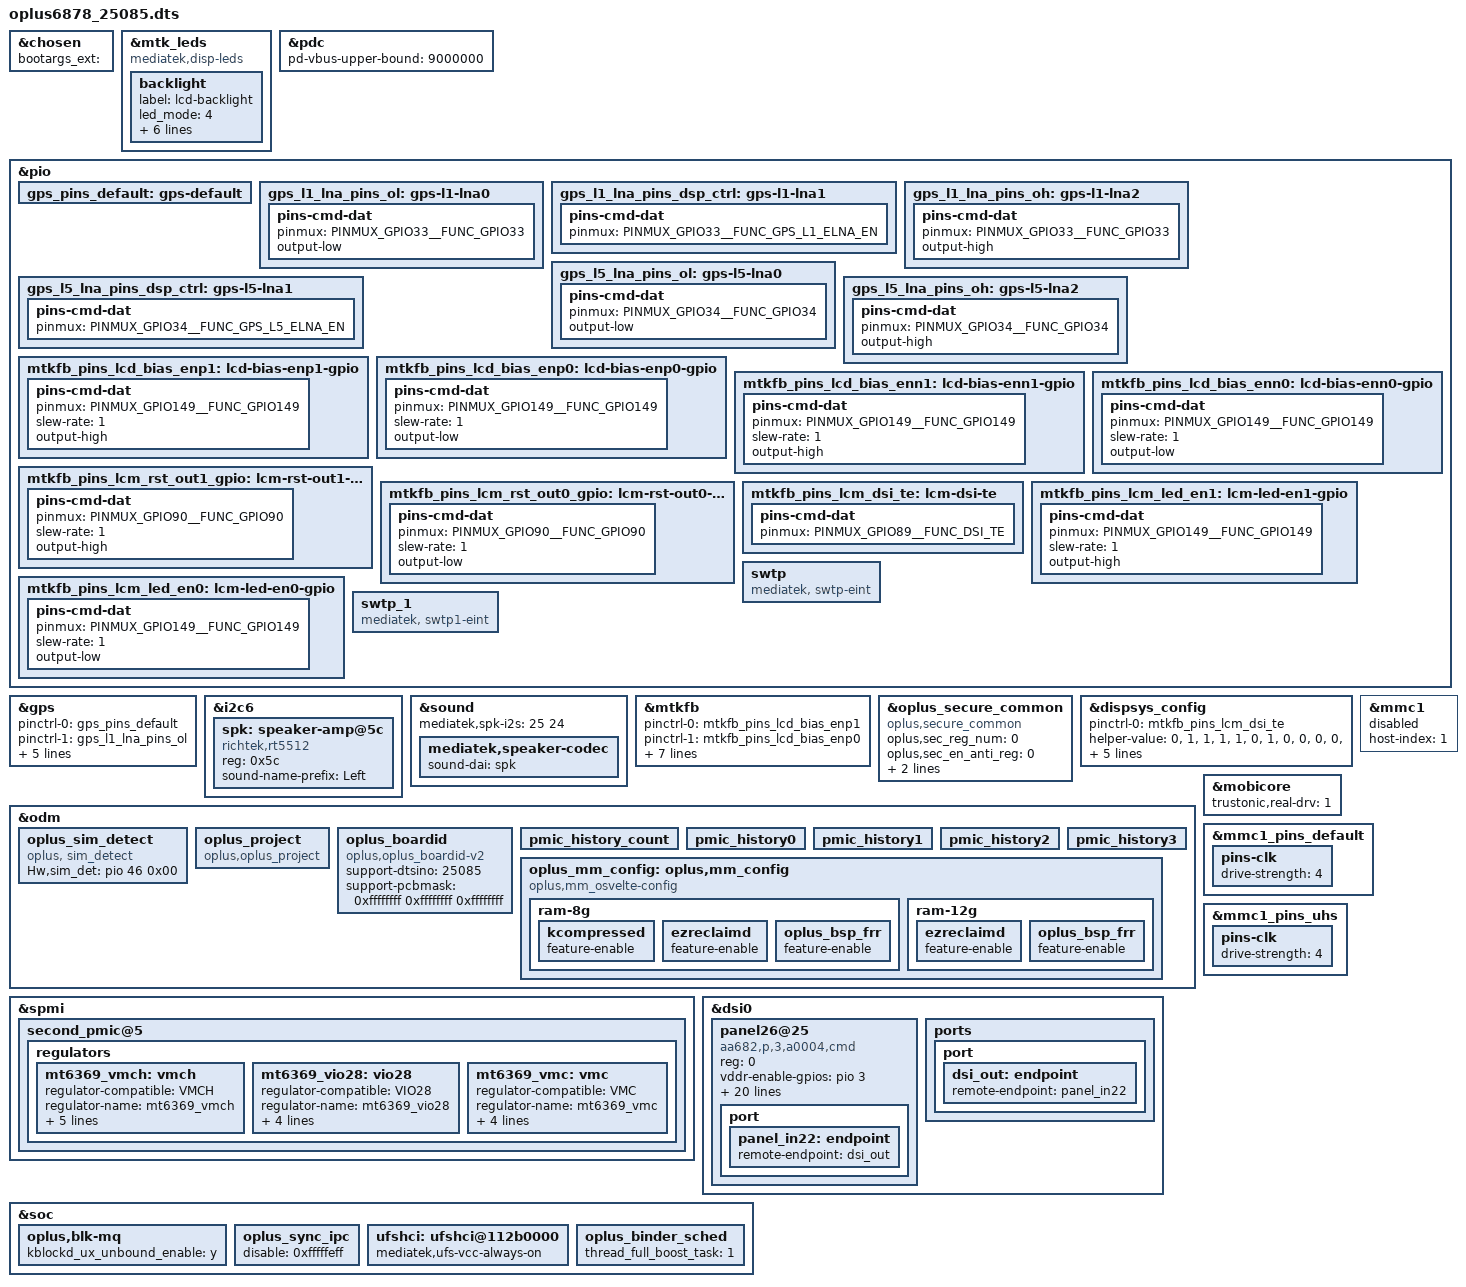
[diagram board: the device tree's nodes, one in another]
// SPDX-License-Identifier: (GPL-2.0 OR MIT)

/*
 * Copyright (C) 2022 MediaTek Inc.
 */
/dts-v1/;
/plugin/;
#include <dt-bindings/interrupt-controller/arm-gic.h>
#include <dt-bindings/interrupt-controller/irq.h>
#include <dt-bindings/phy/phy.h>
#include <dt-bindings/pinctrl/mt6878-pinfunc.h>
#include "mediatek/nfc/mt6878_Jinx-M_thn31s.dtsi"
#include "mediatek/kjinxm_regulator_wl2866d.dtsi"
#if 0
#include <dt-bindings/pinctrl/mt6897-pinfunc.h>
#endif

/* #ifdef OPLUS_FEATURE_SENSOR */
#include "mediatek/oplus_sensor_25085.dtsi"
/* #endif */

/* #ifdef OPLUS_FEATURE_SENSOR */
#include "mediatek/oplus_misc_25085.dtsi"
/* #endif */

/* #ifdef OPLUS_FEATURE_CHG_BASIC */
#include "mediatek/oplus_charge_jinxm_domestic.dtsi"
/* #endif */

/* #ifdef OPLUS_FEATURE_FINGERPRINT */
#include "mediatek/oplus_uff_25085_25329.dtsi"
/* #endif */

/* Add for jinx-m pt device-tree */
#include "mediatek/oplus_pt_25085.dtsi"

&chosen {
bootargs_ext = "";
};

&mtk_leds {
	compatible = "mediatek,disp-leds";
	status = "okay";

	backlight {
		label = "lcd-backlight";
		led_mode = <4>;
		min-brightness = <1>;
		max-brightness = <4094>;
		max-hw-brightness = <4094>;
		led-bits = <13>;
		trans-bits = <13>;
		default-state = "half";
	};
};

&pdc {
	pd-vbus-upper-bound = <9000000>;
};

#if 0

&connfem {
/* Enable epa_elna node to support Wifi & BT ePA/eLNA FEM on customer load */
#if 0
	epa-elna {
		parts = <&wlan7207h &wlan7207c>;
		wifi {
			flags-0 {
				open-loop;
			};
		};
		bt {
			flags-0 {
				/* choose one of: epa-elna/epa/elna/bypass */
				epa-elna;
			};
		};
	};
#endif
};
#endif

/* GPS GPIO standardization start */
&pio {
	gps_pins_default: gps-default {
	};
	gps_l1_lna_pins_ol: gps-l1-lna0 {
		pins-cmd-dat {
			pinmux = <PINMUX_GPIO33__FUNC_GPIO33>;
			output-low;
		};
	};
	gps_l1_lna_pins_dsp_ctrl: gps-l1-lna1 {
		pins-cmd-dat {
			pinmux = <PINMUX_GPIO33__FUNC_GPS_L1_ELNA_EN>;
		};
	};
	gps_l1_lna_pins_oh: gps-l1-lna2 {
		pins-cmd-dat {
			pinmux = <PINMUX_GPIO33__FUNC_GPIO33>;
			output-high;
		};
	};
	gps_l5_lna_pins_ol: gps-l5-lna0 {
		pins-cmd-dat {
			pinmux = <PINMUX_GPIO34__FUNC_GPIO34>;
			output-low;
		};
	};
	gps_l5_lna_pins_dsp_ctrl: gps-l5-lna1 {
		pins-cmd-dat {
			pinmux = <PINMUX_GPIO34__FUNC_GPS_L5_ELNA_EN>;
		};
	};
	gps_l5_lna_pins_oh: gps-l5-lna2 {
		pins-cmd-dat {
			pinmux = <PINMUX_GPIO34__FUNC_GPIO34>;
			output-high;
		};
	};
};
&gps {
	pinctrl-names = "default",
		"gps_l1_lna_disable",
		"gps_l1_lna_dsp_ctrl",
		"gps_l1_lna_enable",
		"gps_l5_lna_disable",
		"gps_l5_lna_dsp_ctrl",
		"gps_l5_lna_enable";
	pinctrl-0 = <&gps_pins_default>;
	pinctrl-1 = <&gps_l1_lna_pins_ol>;
	pinctrl-2 = <&gps_l1_lna_pins_dsp_ctrl>;
	pinctrl-3 = <&gps_l1_lna_pins_oh>;
	pinctrl-4 = <&gps_l5_lna_pins_ol>;
	pinctrl-5 = <&gps_l5_lna_pins_dsp_ctrl>;
	pinctrl-6 = <&gps_l5_lna_pins_oh>;
	status = "okay";
};
/* GPS GPIO standardization end */

&i2c6 {
	spk: speaker-amp@5c {
		compatible = "richtek,rt5512";
		#address-cells = <1>;
		#size-cells = <0>;
		#sound-dai-cells = <0>;
		reg = <0x5c>;
		status = "okay";
		sound-name-prefix = "Left";
	};
};

&sound {
	mediatek,spk-i2s = <25 24>;
	mediatek,speaker-codec {
		sound-dai = <&spk>;
	};
};



&mtkfb {
	pinctrl-names = "lcd_bias_enp1_gpio", "lcd_bias_enp0_gpio",
		"lcd_bias_enn1_gpio", "lcd_bias_enn0_gpio",
		"lcm_rst_out1_gpio", "lcm_rst_out0_gpio",
		"mode_te_te", "lcm_led_en1_gpio", "lcm_led_en0_gpio";
	pinctrl-0 = <&mtkfb_pins_lcd_bias_enp1>;
	pinctrl-1 = <&mtkfb_pins_lcd_bias_enp0>;
	pinctrl-2 = <&mtkfb_pins_lcd_bias_enn1>;
	pinctrl-3 = <&mtkfb_pins_lcd_bias_enn0>;
	pinctrl-4 = <&mtkfb_pins_lcm_rst_out1_gpio>;
	pinctrl-5 = <&mtkfb_pins_lcm_rst_out0_gpio>;
	pinctrl-6 = <&mtkfb_pins_lcm_dsi_te>;
	pinctrl-7 = <&mtkfb_pins_lcm_led_en1>;
	pinctrl-8 = <&mtkfb_pins_lcm_led_en0>;

	status = "okay";
};

&oplus_secure_common {
    compatible = "oplus,secure_common";
    oplus,sec_reg_num = <0>;
    oplus,sec_en_anti_reg = <0>;
    oplus,sec_override1_reg = <0>;
    oplus,override1_en_value = <0>;
};

&pio {
	mtkfb_pins_lcd_bias_enp1: lcd-bias-enp1-gpio {
		pins-cmd-dat {
			pinmux = <PINMUX_GPIO149__FUNC_GPIO149>;
			slew-rate = <1>;
			output-high;
		};
	};

	mtkfb_pins_lcd_bias_enp0: lcd-bias-enp0-gpio {
		pins-cmd-dat {
			pinmux = <PINMUX_GPIO149__FUNC_GPIO149>;
			slew-rate = <1>;
			output-low;
		};
	};

	mtkfb_pins_lcd_bias_enn1: lcd-bias-enn1-gpio {
		pins-cmd-dat {
			pinmux = <PINMUX_GPIO149__FUNC_GPIO149>;
			slew-rate = <1>;
			output-high;
		};
	};

	mtkfb_pins_lcd_bias_enn0: lcd-bias-enn0-gpio {
		pins-cmd-dat {
			pinmux = <PINMUX_GPIO149__FUNC_GPIO149>;
			slew-rate = <1>;
			output-low;
		};
	};

	mtkfb_pins_lcm_rst_out1_gpio: lcm-rst-out1-gpio {
		pins-cmd-dat {
			pinmux = <PINMUX_GPIO90__FUNC_GPIO90>;
			slew-rate = <1>;
			output-high;
		};
	};

	mtkfb_pins_lcm_rst_out0_gpio: lcm-rst-out0-gpio {
		pins-cmd-dat {
			pinmux = <PINMUX_GPIO90__FUNC_GPIO90>;
			slew-rate = <1>;
			output-low;
		};
	};
	mtkfb_pins_lcm_dsi_te: lcm-dsi-te {
		pins-cmd-dat {
			pinmux = <PINMUX_GPIO89__FUNC_DSI_TE>;
		};
	};

	mtkfb_pins_lcm_led_en1: lcm-led-en1-gpio {
		pins-cmd-dat {
			pinmux = <PINMUX_GPIO149__FUNC_GPIO149>;
			slew-rate = <1>;
			output-high;
		};
	};

	mtkfb_pins_lcm_led_en0: lcm-led-en0-gpio {
		pins-cmd-dat {
			pinmux = <PINMUX_GPIO149__FUNC_GPIO149>;
			slew-rate = <1>;
			output-low;
		};
	};
};

&dispsys_config {
	pinctrl-names = "mode_te_te";
	pinctrl-0 = <&mtkfb_pins_lcm_dsi_te>;
	status = "okay";

	helper-value = <0>, /*MTK_DRM_OPT_STAGE*/
				<1>, /*MTK_DRM_OPT_USE_CMDQ*/
				<1>, /*MTK_DRM_OPT_USE_M4U*/
				<1>, /*MTK_DRM_OPT_MMQOS_SUPPORT*/
				<1>, /*MTK_DRM_OPT_MMDVFS_SUPPORT*/
				<0>, /*MTK_DRM_OPT_SODI_SUPPORT*/
				<1>, /*MTK_DRM_OPT_IDLE_MGR*/
				<0>, /*MTK_DRM_OPT_IDLEMGR_SWTCH_DECOUPLE*/
				<0>, /*MTK_DRM_OPT_IDLEMGR_BY_REPAINT*/
				<0>, /*MTK_DRM_OPT_IDLEMGR_ENTER_ULPS*/
				<0>, /*MTK_DRM_OPT_IDLEMGR_KEEP_LP11*/
				<0>, /*MTK_DRM_OPT_DYNAMIC_RDMA_GOLDEN_SETTING*/
				<1>, /*MTK_DRM_OPT_IDLEMGR_DISABLE_ROUTINE_IRQ*/
				<1>, /*MTK_DRM_OPT_IDLEMGR_ASYNC*/
				<0>, /*MTK_DRM_OPT_MET_LOG*/
				<1>, /*MTK_DRM_OPT_USE_PQ*/
				<1>, /*MTK_DRM_OPT_ESD_CHECK_RECOVERY*/
				<1>, /*MTK_DRM_OPT_ESD_CHECK_SWITCH*/
				<1>, /*MTK_DRM_OPT_PRESENT_FENCE*/
				<0>, /*MTK_DRM_OPT_RDMA_UNDERFLOW_AEE*/
				<1>, /*MTK_DRM_OPT_DSI_UNDERRUN_AEE*/
				<0>, /*MTK_DRM_OPT_ODDMR_OD_AEE*/
				<0>, /*MTK_DRM_OPT_ODDMR_DMR_AEE*/
				<1>, /*MTK_DRM_OPT_HRT*/
				<0>, /*MTK_DRM_OPT_HRT_MODE*/
				<0>, /*MTK_DRM_OPT_DELAYED_TRIGGER*/
				<1>, /*MTK_DRM_OPT_OVL_EXT_LAYER*/
				<1>, /*MTK_DRM_OPT_AOD*/
				<1>, /*MTK_DRM_OPT_RPO*/
				<0>, /*MTK_DRM_OPT_DUAL_PIPE*/
				<0>, /*MTK_DRM_OPT_DC_BY_HRT*/
				<0>, /*MTK_DRM_OPT_OVL_WCG*/
				<0>, /*MTK_DRM_OPT_OVL_SBCH*/
				<1>, /*MTK_DRM_OPT_COMMIT_NO_WAIT_VBLANK*/
				<0>, /*MTK_DRM_OPT_MET*/
				<0>, /*MTK_DRM_OPT_REG_PARSER_RAW_DUMP*/
				<0>, /*MTK_DRM_OPT_VP_PQ*/
				<0>, /*MTK_DRM_OPT_GAME_PQ*/
				<0>, /*MTK_DRM_OPT_MMPATH*/
				<0>, /*MTK_DRM_OPT_HBM*/
				<0>, /*MTK_DRM_OPT_VDS_PATH_SWITCH*/
				<0>, /*MTK_DRM_OPT_LAYER_REC*/
				<1>, /*MTK_DRM_OPT_CLEAR_LAYER*/
				<1>, /*MTK_DRM_OPT_LFR*/
				<0>, /*MTK_DRM_OPT_SF_PF*/
				<1>, /*MTK_DRM_OPT_DYN_MIPI_CHANGE*/
				<0>, /*MTK_DRM_OPT_PRIM_DUAL_PIPE*/
				<0>, /*MTK_DRM_OPT_MSYNC2_0*/
				<1>, /*MTK_DRM_OPT_MML_PRIMARY*/
				<0>, /*MTK_DRM_OPT_MML_SUPPORT_CMD_MODE*/
				<0>, /*MTK_DRM_OPT_MML_PQ*/
				<0>, /*MTK_DRM_OPT_MML_IR*/
				<0>, /*MTK_DRM_OPT_DUAL_TE*/
				<0>, /*MTK_DRM_OPT_RES_SWITCH*/
				<0>, /*MTK_DRM_OPT_PREFETCH_TE*/
				<0>, /*MTK_DRM_OPT_VIDLE_APSRC_OFF*/
				<0>, /*MTK_DRM_OPT_VIDLE_DSI_PLL_OFF*/
				<0>, /*MTK_DRM_OPT_CHECK_TRIGGER_MERGE*/
				<0>, /*MTK_DRM_OPT_VIRTUAL_DISP*/
				<1>, /*MTK_DRM_OPT_OVL_BW_MONITOR*/
				<0>, /*MTK_DRM_OPT_GPU_CACHE*/
				<1>, /*MTK_DRM_OPT_SPHRT*/
				<1>, /*MTK_DRM_OPT_SDPA_OVL_SWITCH*/
				<0>, /*MTK_DRM_OPT_HRT_BY_LARB*/
				<1>, /*MTK_DRM_OPT_LAYERING_RULE_BY_LARB*/
				<1>, /*MTK_DRM_OPT_RES_SWITCH_ON_AP*/
				<0>, /*MTK_DRM_OPT_TILE_OVERHEAD*/
				<1>, /*MTK_DRM_OPT_VIDLE_TOP_EN*/
				<0>, /*MTK_DRM_OPT_VIDLE_MTCMOS_DT_EN*/
				<1>, /*MTK_DRM_OPT_VIDLE_MMINFRA_DT_EN*/
				<0>, /*MTK_DRM_OPT_VIDLE_DVFS_DT_EN*/
				<0>, /*MTK_DRM_OPT_VIDLE_QOS_DT_EN*/
				<0>, /*MTK_DRM_OPT_VIDLE_GCE_TS_EN*/
				<0>, /*MTK_DRM_OPT_VIDLE_DECOUPLE_MODE*/
				<0>, /*MTK_DRM_OPT_VIDLE_VDO_PANEL*/
				<0>, /*MTK_DRM_OPT_VIDLE_HOME_SCREEN_IDLE*/
				<0>, /*MTK_DRM_OPT_DPC_PRE_TE_EN*/
				<0>; /*"MTK_DRM_OPT_PER_LARB_PORT_PEAK"*/
};

&odm {
/* Add for sim detect */
    oplus_sim_detect {
        compatible = "oplus, sim_detect";
        Hw,sim_det = <&pio 46 0x00>;
    };
};

/* Alpha-H does not use SD card, vmch is used by panel VCI */
&mmc1 {
	host-index = <1>;
	status = "disabled";
};

/*mt6369-vmch*/
&spmi {
	second_pmic@5 {
		regulators {
			mt6369_vmch: vmch {
				regulator-compatible = "VMCH";
				regulator-name = "mt6369_vmch";
				regulator-min-microvolt = <1200000>;
				regulator-max-microvolt = <3500000>;
				regulator-enable-ramp-delay = <680>;
				regulator-allowed-modes = <0 2>;
				regulator-always-on;
			};
			mt6369_vio28: vio28 {
				regulator-compatible = "VIO28";
				regulator-name = "mt6369_vio28";
				regulator-min-microvolt = <1200000>;
				regulator-max-microvolt = <3500000>;
				regulator-enable-ramp-delay = <680>;
				regulator-allowed-modes = <0 2>;
			};
			mt6369_vmc: vmc {
				regulator-compatible = "VMC";
				regulator-name = "mt6369_vmc";
				regulator-min-microvolt = <1200000>;
				regulator-max-microvolt = <3500000>;
				regulator-enable-ramp-delay = <680>;
				regulator-allowed-modes = <0 2>;
			};
		};
	};
};

&dsi0 {
	status = "okay";
	#address-cells = <1>;
	#size-cells = <0>;
	panel26@25 {
		compatible = "aa682,p,3,a0004,cmd";
		reg = <0>;
		vddr-enable-gpios = <&pio 3 0>;
		vddi-supply = <&mt6369_vmc>;
		vci-supply = <&mt6369_vio28>;
		reset-gpios = <&pio 90 0>;
		oplus,panel-max-brightness=<4094>;
		oplus,dsi-serial-number-enabled= <1>;
		oplus,dsi-serial-number-switch-page;
		oplus,dsi-serial-number-index= <0>;
		oplus,dsi-serial-number-switch-page-command= <0xFF 0x08 0x38 0x1D>;
		oplus,dsi-serial-number-default-switch-page-command= <0xFF 0x08 0x38 0x00>;
		oplus,dsi-serial-number-reg= <0x81>;
		oplus,dsi-serial-number-read-count= <7>;
		res-switch = <2>;
		/* OFP config */
		oplus,ofp-fp-type = <0x10>;
		oplus,ofp-fp-local-hbm-calibration;
		oplus,ofp-longrui-aod-config = <0x02>;
		/* fp red lhbm or hbm reg*/
		oplus,ofp-read-hbm-reg = <0x95>;
		oplus,ofp-check-hbm-reg-value = <0x13>;
		oplus,ofp-check-hbm-reg-mask = <0xFF>;
		pinctrl-names = "default";
		port {
			panel_in22: endpoint {
				remote-endpoint = <&dsi_out>;
			};
		};
	};

	ports {
		port {
			dsi_out: endpoint {
				remote-endpoint = <&panel_in22>;
			};
		};
	};
};

&odm {
    /*OPLUS_FEATURE_OEM_OCDT oppo project start */
	oplus_project:oplus_project {
		compatible = "oplus,oplus_project";
	};
    
    oplus_boardid:oplus_boardid {
		compatible = "oplus,oplus_boardid-v2";
		support-dtsino=<25085>;//only one u32
		/*first one is low 32bit, last one is highest 32bit, must be 32-bit for 4gpios*/
		support-pcbmask=<0xffffffff 0xffffffff 0xffffffff>;
	};

	pmic_history_count:pmic_history_count {
	};
	pmic_history0:pmic_history0 {
	};
	pmic_history1:pmic_history1 {
	};
	pmic_history2:pmic_history2 {
	};
	pmic_history3:pmic_history3 {
	};

};

//Network RF add SWTP
&pio {
	//#ifdef OPLUS_VENDOR_SWTP
	swtp: swtp {
		compatible = "mediatek, swtp-eint";
	};
	 swtp_1: swtp_1 {
		compatible = "mediatek, swtp1-eint";
	};
	//#endif  /*OPLUS_VENDOR_SWTP*/
};

/*
 * Trustonic Mobilecore real driver
 */
&mobicore{
        trustonic,real-drv = <1>;
};

//#ifdef OPLUS_FEATURE_STORAGE
&mmc1_pins_default {
	pins-clk {
		drive-strength = <4>;
	};
};
&mmc1_pins_uhs {
	pins-clk {
		drive-strength = <4>;
	};
};
//#endif /*OPLUS_FEATURE_STORAGE*/

&soc {
	//@Kernel.Storage, 2024/10/16, add for blk-mq.c kblockd_ux_unbound_enable
	oplus,blk-mq {
		kblockd_ux_unbound_enable = "y";
	};
	oplus_sync_ipc {
        disable = <0xfffffeff>;
    };
	//@Kernel.Storage, 2025/06/12, add for ufs-mediatek.c ufs-vcc-always-on
	ufshci: ufshci@112b0000 {
		mediatek,ufs-vcc-always-on;
	};
	//#ifdef CONFIG_OPLUS_BINDER_STRATEGY
	oplus_binder_sched {
		thread_full_boost_task = <1>;
	};
	//#endif
};

&odm {
	oplus_mm_config: oplus,mm_config {
		compatible = "oplus,mm_osvelte-config";
		ram-8g {
			kcompressed {
				feature-enable;
			};
			ezreclaimd {
				feature-enable;
			};
			oplus_bsp_frr {
				feature-enable;
			};
		};
		ram-12g {
			ezreclaimd {
				feature-enable;
			};
			oplus_bsp_frr {
				feature-enable;
			};
		};
	};
};

#include <oplus6878_25085/cust.dtsi>
#include "mediatek/cust_mt6878_kjinxm_camera_v4l2.dtsi"
#include "mediatek/cust_k6878_connfem.dtsi"
#include "mediatek/cust_mt6878_25329_audio.dtsi"
#include "mediatek/oplus_tp_25085.dtsi"
#include "cust_mt6878_24035_thermal.dtsi"
#include "cust_mt6878_25085_thermal.dtsi"
/*End of this file, DO NOT ADD ANYTHING HERE*/
